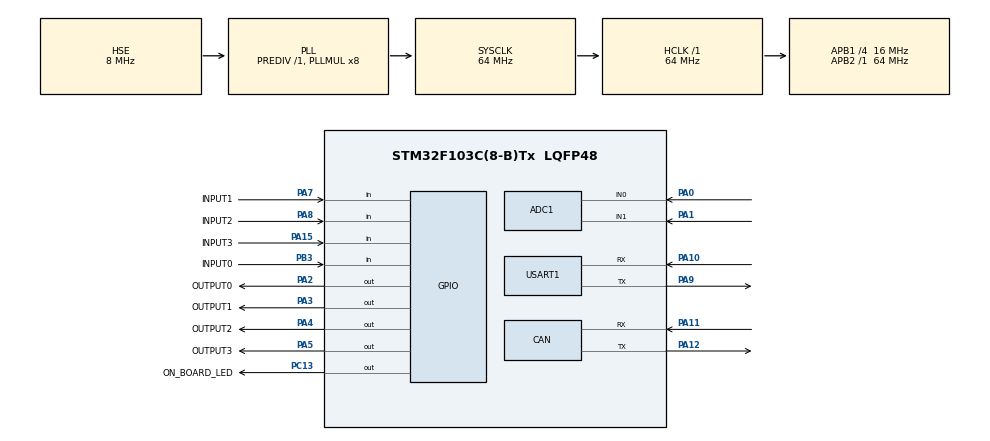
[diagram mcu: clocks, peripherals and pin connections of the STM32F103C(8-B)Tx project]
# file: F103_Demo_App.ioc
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ADC1.Channel-0\#ChannelRegularConversion=ADC_CHANNEL_0
ADC1.NbrOfConversionFlag=1
ADC1.Rank-0\#ChannelRegularConversion=1
ADC1.SamplingTime-0\#ChannelRegularConversion=ADC_SAMPLETIME_55CYCLES_5
ADC1.master=1
CAN.BS1=CAN_BS1_13TQ
CAN.BS2=CAN_BS2_2TQ
CAN.CalculateTimeBit=16000
CAN.CalculateTimeQuantum=1000.0
Mcu.Family=STM32F1
Mcu.Name=STM32F103C(8-B)Tx
Mcu.Package=LQFP48
NVIC.PriorityGroup=NVIC_PRIORITYGROUP_4
NVIC.USB_LP_CAN1_RX0_IRQn=true\:0\:0\:false\:false\:true\:true\:true
PA0-WKUP.Signal=ADCx_IN0
PA1.Signal=ADCx_IN1
PA10.Mode=Asynchronous
PA10.Signal=USART1_RX
PA11.Mode=Master
PA11.Signal=CAN_RX
PA12.Mode=Master
PA12.Signal=CAN_TX
PA15.GPIO_Label=INPUT3
PA15.Signal=GPIO_Input
PA2.GPIO_Label=OUTPUT0
PA2.Signal=GPIO_Output
PA3.GPIO_Label=OUTPUT1
PA3.Signal=GPIO_Output
PA4.GPIO_Label=OUTPUT2
PA4.Signal=GPIO_Output
PA5.GPIO_Label=OUTPUT3
PA5.Signal=GPIO_Output
PA7.GPIO_Label=INPUT1
PA7.Signal=GPIO_Input
PA8.GPIO_Label=INPUT2
PA8.Signal=GPIO_Input
PA9.Mode=Asynchronous
PA9.Signal=USART1_TX
PB3.GPIO_Label=INPUT0
PB3.Signal=GPIO_Input
PC13-TAMPER-RTC.GPIO_Label=ON_BOARD_LED
PC13-TAMPER-RTC.Signal=GPIO_Output
PD0-OSC_IN.Mode=HSE-External-Oscillator
PD0-OSC_IN.Signal=RCC_OSC_IN
PD1-OSC_OUT.Mode=HSE-External-Oscillator
PD1-OSC_OUT.Signal=RCC_OSC_OUT
ProjectManager.HeapSize=0x200
ProjectManager.StackSize=0x400
ProjectManager.TargetToolchain=Makefile
RCC.ADCPresc=RCC_ADCPCLK2_DIV8
RCC.AHBFreq_Value=64000000
RCC.APB1CLKDivider=RCC_HCLK_DIV4
RCC.APB1Freq_Value=16000000
RCC.APB1TimFreq_Value=32000000
RCC.APB2Freq_Value=64000000
RCC.APB2TimFreq_Value=64000000
RCC.HCLKFreq_Value=64000000
RCC.PLLMUL=RCC_PLL_MUL8
RCC.PLLSourceVirtual=RCC_PLLSOURCE_HSE
RCC.SYSCLKFreq_VALUE=64000000
RCC.SYSCLKSource=RCC_SYSCLKSOURCE_PLLCLK
RCC.USBFreq_Value=64000000
SH.ADCx_IN0.0=ADC1_IN0,IN0
SH.ADCx_IN1.0=ADC1_IN1,IN1
USART1.VirtualMode=VM_ASYNC
VP_SYS_VS_ND.Mode=No_Debug
board=custom

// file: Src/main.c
/* USER CODE BEGIN Header */
/**
  ******************************************************************************
  * @file           : main.c
  * @brief          : Main program body
  ******************************************************************************
  * @attention
  *
  * <h2><center>&copy; Copyright (c) 2020 STMicroelectronics.
  * All rights reserved.</center></h2>
  *
  * This software component is licensed by ST under BSD 3-Clause license,
  * the "License"; You may not use this file except in compliance with the
  * License. You may obtain a copy of the License at:
  *                        opensource.org/licenses/BSD-3-Clause
  *
  ******************************************************************************
  */
/* USER CODE END Header */

#include "main.h"

ADC_HandleTypeDef hadc1;

CAN_HandleTypeDef hcan;

UART_HandleTypeDef huart1;

void SystemClock_Config(void);
static void MX_GPIO_Init(void);
static void MX_ADC1_Init(void);
static void MX_CAN_Init(void);
static void MX_USART1_UART_Init(void);

int main(void)
{

  /* MCU Configuration--------------------------------------------------------*/

  /* Reset of all peripherals, Initializes the Flash interface and the Systick. */
  HAL_Init();

  /* Configure the system clock */
  SystemClock_Config();

  /* Initialize all configured peripherals */
  MX_GPIO_Init();
  MX_ADC1_Init();
  MX_CAN_Init();
  MX_USART1_UART_Init();

  /* Infinite loop */
  while (1)
  {

    /* USER CODE BEGIN 3 */
	  HAL_GPIO_TogglePin(ON_BOARD_LED_GPIO_Port,ON_BOARD_LED_Pin);
	  HAL_Delay(150);
  }
  /* USER CODE END 3 */
}

void SystemClock_Config(void)
{
  RCC_OscInitTypeDef RCC_OscInitStruct = {0};
  RCC_ClkInitTypeDef RCC_ClkInitStruct = {0};
  RCC_PeriphCLKInitTypeDef PeriphClkInit = {0};

  /** Initializes the CPU, AHB and APB busses clocks
  */
  RCC_OscInitStruct.OscillatorType = RCC_OSCILLATORTYPE_HSE;
  RCC_OscInitStruct.HSEState = RCC_HSE_ON;
  RCC_OscInitStruct.HSEPredivValue = RCC_HSE_PREDIV_DIV1;
  RCC_OscInitStruct.HSIState = RCC_HSI_ON;
  RCC_OscInitStruct.PLL.PLLState = RCC_PLL_ON;
  RCC_OscInitStruct.PLL.PLLSource = RCC_PLLSOURCE_HSE;
  RCC_OscInitStruct.PLL.PLLMUL = RCC_PLL_MUL8;
  if (HAL_RCC_OscConfig(&RCC_OscInitStruct) != HAL_OK)
  {
    Error_Handler();
  }
  /** Initializes the CPU, AHB and APB busses clocks
  */
  RCC_ClkInitStruct.ClockType = RCC_CLOCKTYPE_HCLK|RCC_CLOCKTYPE_SYSCLK
                              |RCC_CLOCKTYPE_PCLK1|RCC_CLOCKTYPE_PCLK2;
  RCC_ClkInitStruct.SYSCLKSource = RCC_SYSCLKSOURCE_PLLCLK;
  RCC_ClkInitStruct.AHBCLKDivider = RCC_SYSCLK_DIV1;
  RCC_ClkInitStruct.APB1CLKDivider = RCC_HCLK_DIV4;
  RCC_ClkInitStruct.APB2CLKDivider = RCC_HCLK_DIV1;

  if (HAL_RCC_ClockConfig(&RCC_ClkInitStruct, FLASH_LATENCY_2) != HAL_OK)
  {
    Error_Handler();
  }
  PeriphClkInit.PeriphClockSelection = RCC_PERIPHCLK_ADC;
  PeriphClkInit.AdcClockSelection = RCC_ADCPCLK2_DIV8;
  if (HAL_RCCEx_PeriphCLKConfig(&PeriphClkInit) != HAL_OK)
  {
    Error_Handler();
  }
}

static void MX_ADC1_Init(void)
{

  ADC_ChannelConfTypeDef sConfig = {0};

  /** Common config
  */
  hadc1.Instance = ADC1;
  hadc1.Init.ScanConvMode = ADC_SCAN_DISABLE;
  hadc1.Init.ContinuousConvMode = DISABLE;
  hadc1.Init.DiscontinuousConvMode = DISABLE;
  hadc1.Init.ExternalTrigConv = ADC_SOFTWARE_START;
  hadc1.Init.DataAlign = ADC_DATAALIGN_RIGHT;
  hadc1.Init.NbrOfConversion = 1;
  if (HAL_ADC_Init(&hadc1) != HAL_OK)
  {
    Error_Handler();
  }
  /** Configure Regular Channel
  */
  sConfig.Channel = ADC_CHANNEL_0;
  sConfig.Rank = ADC_REGULAR_RANK_1;
  sConfig.SamplingTime = ADC_SAMPLETIME_55CYCLES_5;
  if (HAL_ADC_ConfigChannel(&hadc1, &sConfig) != HAL_OK)
  {
    Error_Handler();
  }

}

static void MX_CAN_Init(void)
{

  hcan.Instance = CAN1;
  hcan.Init.Prescaler = 16;
  hcan.Init.Mode = CAN_MODE_NORMAL;
  hcan.Init.SyncJumpWidth = CAN_SJW_1TQ;
  hcan.Init.TimeSeg1 = CAN_BS1_13TQ;
  hcan.Init.TimeSeg2 = CAN_BS2_2TQ;
  hcan.Init.TimeTriggeredMode = DISABLE;
  hcan.Init.AutoBusOff = DISABLE;
  hcan.Init.AutoWakeUp = DISABLE;
  hcan.Init.AutoRetransmission = DISABLE;
  hcan.Init.ReceiveFifoLocked = DISABLE;
  hcan.Init.TransmitFifoPriority = DISABLE;
  if (HAL_CAN_Init(&hcan) != HAL_OK)
  {
    Error_Handler();
  }

}

static void MX_USART1_UART_Init(void)
{

  huart1.Instance = USART1;
  huart1.Init.BaudRate = 115200;
  huart1.Init.WordLength = UART_WORDLENGTH_8B;
  huart1.Init.StopBits = UART_STOPBITS_1;
  huart1.Init.Parity = UART_PARITY_NONE;
  huart1.Init.Mode = UART_MODE_TX_RX;
  huart1.Init.HwFlowCtl = UART_HWCONTROL_NONE;
  huart1.Init.OverSampling = UART_OVERSAMPLING_16;
  if (HAL_UART_Init(&huart1) != HAL_OK)
  {
    Error_Handler();
  }

}

static void MX_GPIO_Init(void)
{
  GPIO_InitTypeDef GPIO_InitStruct = {0};

  /* GPIO Ports Clock Enable */
  __HAL_RCC_GPIOC_CLK_ENABLE();
  __HAL_RCC_GPIOD_CLK_ENABLE();
  __HAL_RCC_GPIOA_CLK_ENABLE();
  __HAL_RCC_GPIOB_CLK_ENABLE();

  /*Configure GPIO pin Output Level */
  HAL_GPIO_WritePin(ON_BOARD_LED_GPIO_Port, ON_BOARD_LED_Pin, GPIO_PIN_RESET);

  /*Configure GPIO pin Output Level */
  HAL_GPIO_WritePin(GPIOA, OUTPUT0_Pin|OUTPUT1_Pin|OUTPUT2_Pin|OUTPUT3_Pin, GPIO_PIN_RESET);

  /*Configure GPIO pin : ON_BOARD_LED_Pin */
  GPIO_InitStruct.Pin = ON_BOARD_LED_Pin;
  GPIO_InitStruct.Mode = GPIO_MODE_OUTPUT_PP;
  GPIO_InitStruct.Pull = GPIO_NOPULL;
  GPIO_InitStruct.Speed = GPIO_SPEED_FREQ_LOW;
  HAL_GPIO_Init(ON_BOARD_LED_GPIO_Port, &GPIO_InitStruct);

  /*Configure GPIO pins : OUTPUT0_Pin OUTPUT1_Pin OUTPUT2_Pin OUTPUT3_Pin */
  GPIO_InitStruct.Pin = OUTPUT0_Pin|OUTPUT1_Pin|OUTPUT2_Pin|OUTPUT3_Pin;
  GPIO_InitStruct.Mode = GPIO_MODE_OUTPUT_PP;
  GPIO_InitStruct.Pull = GPIO_NOPULL;
  GPIO_InitStruct.Speed = GPIO_SPEED_FREQ_LOW;
  HAL_GPIO_Init(GPIOA, &GPIO_InitStruct);

  /*Configure GPIO pins : INPUT1_Pin INPUT2_Pin INPUT3_Pin */
  GPIO_InitStruct.Pin = INPUT1_Pin|INPUT2_Pin|INPUT3_Pin;
  GPIO_InitStruct.Mode = GPIO_MODE_INPUT;
  GPIO_InitStruct.Pull = GPIO_NOPULL;
  HAL_GPIO_Init(GPIOA, &GPIO_InitStruct);

  /*Configure GPIO pin : INPUT0_Pin */
  GPIO_InitStruct.Pin = INPUT0_Pin;
  GPIO_InitStruct.Mode = GPIO_MODE_INPUT;
  GPIO_InitStruct.Pull = GPIO_NOPULL;
  HAL_GPIO_Init(INPUT0_GPIO_Port, &GPIO_InitStruct);

}

void Error_Handler(void)
{
}

/************************ (C) COPYRIGHT STMicroelectronics *****END OF FILE****/
